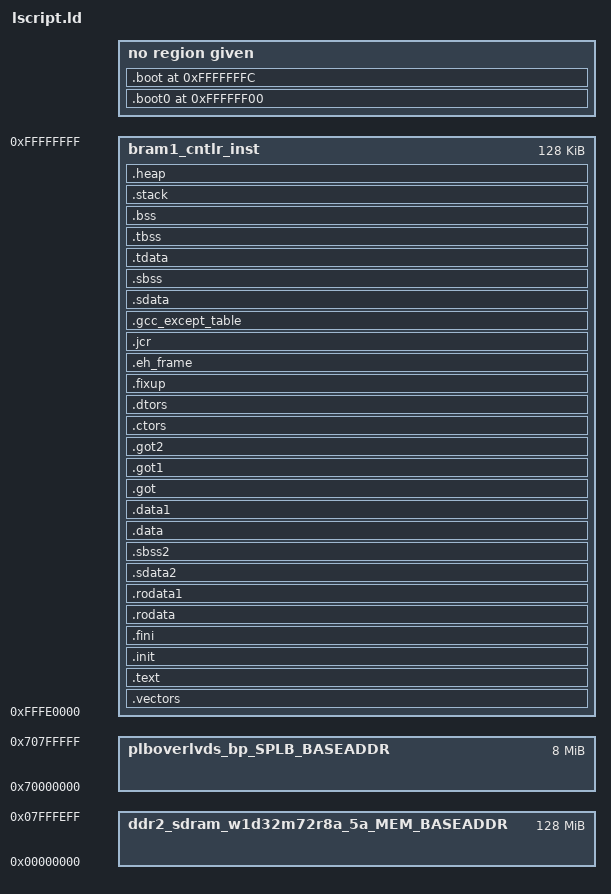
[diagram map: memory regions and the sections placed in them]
/*******************************************************************/
/*                                                                 */
/* This file is automatically generated by linker script generator.*/
/*                                                                 */
/* Version: Xilinx EDK 14.7 EDK_P.20131013                                */
/*                                                                 */
/* Copyright (c) 2010 Xilinx, Inc.  All rights reserved.           */
/*                                                                 */
/* Description : PowerPC440 Linker Script                          */
/*                                                                 */
/*******************************************************************/

_STACK_SIZE = DEFINED(_STACK_SIZE) ? _STACK_SIZE : 0x800;
_HEAP_SIZE = DEFINED(_HEAP_SIZE) ? _HEAP_SIZE : 0x800;
/* Define Memories in the system */

MEMORY
{
   bram1_cntlr_inst : ORIGIN = 0xFFFE0000, LENGTH = 0x00020000
   plboverlvds_bp_SPLB_BASEADDR : ORIGIN = 0x70000000, LENGTH = 0x00800000
   ddr2_sdram_w1d32m72r8a_5a_MEM_BASEADDR : ORIGIN = 0x00000000, LENGTH = 0x07FFFF00
}

/* Specify the default entry point to the program */

ENTRY(_boot)
STARTUP(boot.o)

/* Define the sections, and where they are mapped in memory */

SECTIONS
{
.vectors : {
   __vectors_start = .;
   *(.vectors)
   __vectors_end = .;
} > bram1_cntlr_inst

.text : {
   *(.text)
   *(.text.*)
   *(.gnu.linkonce.t.*)
} > bram1_cntlr_inst

.init : {
   KEEP (*(.init))
} > bram1_cntlr_inst

.fini : {
   KEEP (*(.fini))
} > bram1_cntlr_inst

.rodata : {
   __rodata_start = .;
   *(.rodata)
   *(.rodata.*)
   *(.gnu.linkonce.r.*)
   __rodata_end = .;
} > bram1_cntlr_inst

.rodata1 : {
   __rodata1_start = .;
   *(.rodata1)
   *(.rodata1.*)
   __rodata1_end = .;
} > bram1_cntlr_inst

.sdata2 : {
   __sdata2_start = .;
   *(.sdata2)
   *(.sdata2.*)
   *(.gnu.linkonce.s2.*)
   __sdata2_end = .;
} > bram1_cntlr_inst

.sbss2 : {
   __sbss2_start = .;
   *(.sbss2)
   *(.sbss2.*)
   *(.gnu.linkonce.sb2.*)
   __sbss2_end = .;
} > bram1_cntlr_inst

.data : {
   __data_start = .;
   *(.data)
   *(.data.*)
   *(.gnu.linkonce.d.*)
   __data_end = .;
} > bram1_cntlr_inst

.data1 : {
   __data1_start = .;
   *(.data1)
   *(.data1.*)
   __data1_end = .;
} > bram1_cntlr_inst

.got : {
   *(.got)
} > bram1_cntlr_inst

.got1 : {
   *(.got1)
} > bram1_cntlr_inst

.got2 : {
   *(.got2)
} > bram1_cntlr_inst

.ctors : {
   __CTOR_LIST__ = .;
   ___CTORS_LIST___ = .;
   KEEP (*crtbegin.o(.ctors))
   KEEP (*(EXCLUDE_FILE(*crtend.o) .ctors))
   KEEP (*(SORT(.ctors.*)))
   KEEP (*(.ctors))
   __CTOR_END__ = .;
   ___CTORS_END___ = .;
} > bram1_cntlr_inst

.dtors : {
   __DTOR_LIST__ = .;
   ___DTORS_LIST___ = .;
   KEEP (*crtbegin.o(.dtors))
   KEEP (*(EXCLUDE_FILE(*crtend.o) .dtors))
   KEEP (*(SORT(.dtors.*)))
   KEEP (*(.dtors))
   __DTOR_END__ = .;
   ___DTORS_END___ = .;
} > bram1_cntlr_inst

.fixup : {
   __fixup_start = .;
   *(.fixup)
   __fixup_end = .;
} > bram1_cntlr_inst

.eh_frame : {
   *(.eh_frame)
} > bram1_cntlr_inst

.jcr : {
   *(.jcr)
} > bram1_cntlr_inst

.gcc_except_table : {
   *(.gcc_except_table)
} > bram1_cntlr_inst

.sdata : {
   __sdata_start = .;
   *(.sdata)
   *(.sdata.*)
   *(.gnu.linkonce.s.*)
   __sdata_end = .;
} > bram1_cntlr_inst

.sbss (NOLOAD) : {
   . = ALIGN(4);
   __sbss_start = .;
   *(.sbss)
   *(.sbss.*)
   *(.gnu.linkonce.sb.*)
   *(.scommon)
   . = ALIGN(4);
   __sbss_end = .;
} > bram1_cntlr_inst

.tdata : {
   __tdata_start = .;
   *(.tdata)
   *(.tdata.*)
   *(.gnu.linkonce.td.*)
   __tdata_end = .;
} > bram1_cntlr_inst

.tbss : {
   __tbss_start = .;
   *(.tbss)
   *(.tbss.*)
   *(.gnu.linkonce.tb.*)
   __tbss_end = .;
} > bram1_cntlr_inst

.bss (NOLOAD) : {
   . = ALIGN(4);
   __bss_start = .;
   *(.bss)
   *(.bss.*)
   *(.gnu.linkonce.b.*)
   *(COMMON)
   . = ALIGN(4);
   __bss_end = .;
} > bram1_cntlr_inst

.boot0 0xFFFFFF00 : {
   __boot0_start = .;
   *(.boot0)
   __boot0_end = .;
} 

.boot 0xFFFFFFFC : {
   __boot_start = .;
   *(.boot)
   __boot_end = .;
} 

/* Generate Stack and Heap Sections */

.stack (NOLOAD) : {
   _stack_end = .;
   . += _STACK_SIZE;
   . = ALIGN(16);
   __stack = .;
} > bram1_cntlr_inst

.heap (NOLOAD) : {
   . = ALIGN(16);
   _heap_start = .;
   . += _HEAP_SIZE;
   . = ALIGN(16);
   _heap_end = .;
   _end = .;
} > bram1_cntlr_inst

}

